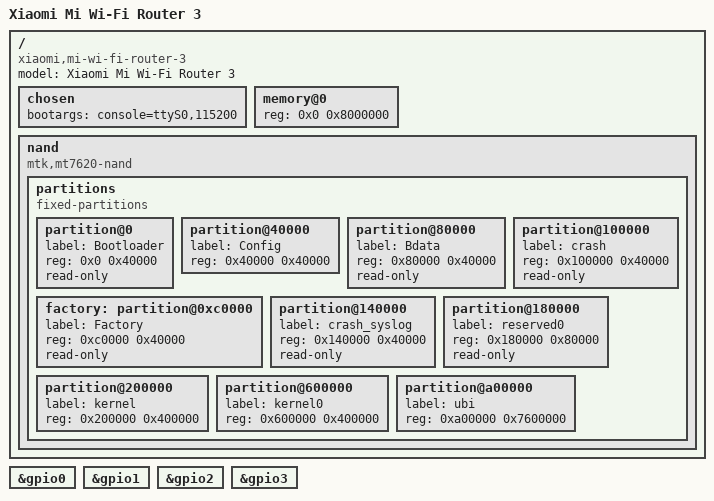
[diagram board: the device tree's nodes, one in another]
// SPDX-License-Identifier: GPL-2.0-or-later OR MIT

#include "mt7620n.dtsi"

#include <dt-bindings/gpio/gpio.h>
#include <dt-bindings/input/input.h>
#include <dt-bindings/leds/common.h>

/ {
	compatible = "xiaomi,mi-wi-fi-router-3", "ralink,mt7620a-soc";
	model = "Xiaomi Mi Wi-Fi Router 3";

	chosen {
		bootargs = "console=ttyS0,115200";
	};

	memory@0 {
		device_type = "memory";
		reg = <0x0 0x8000000>;
	};

	nand {
		compatible = "mtk,mt7620-nand";

		partitions {
			compatible = "fixed-partitions";
			#address-cells = <1>;
			#size-cells = <1>;


			partition@0 {
				label = "Bootloader";
				reg = <0x0 0x40000>;
				read-only;
			};

			partition@40000 {
				label = "Config";
				reg = <0x40000 0x40000>;
			};

			partition@80000 {
				label = "Bdata";
				reg = <0x80000 0x40000>;
				read-only;
			};

			factory: partition@0xc0000 {
				label = "Factory";
				reg = <0xc0000 0x40000>;
				read-only;
			};

			partition@100000 {
				label = "crash";
				reg = <0x100000 0x40000>;
				read-only;
			};

			partition@140000 {
				label = "crash_syslog";
				reg = <0x140000 0x40000>;
				read-only;
			};

			partition@180000 {
				label = "reserved0";
				reg = <0x180000 0x80000>;
				read-only;
			};

			partition@200000 {
				label = "kernel";
				reg = <0x200000 0x400000>;
			};

			partition@600000 {
				label = "kernel0";
				reg = <0x600000 0x400000>;
			};

			partition@a00000 {
				label = "ubi";
				reg = <0xa00000 0x7600000>;
			};

		};
	};
};

&gpio0 {
	status = "okay";
};

&gpio1 {
	status = "okay";
};

&gpio2 {
	status = "okay";
};

&gpio3 {
	status = "okay";
};
